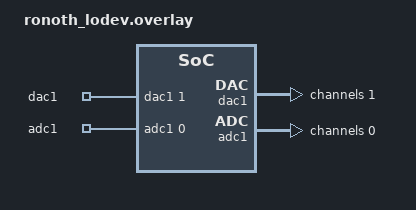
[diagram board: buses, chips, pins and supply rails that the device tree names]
/*
 * Copyright (c) 2021 STMicroelectronics
 *
 * SPDX-License-Identifier: Apache-2.0
 */

/*
 * DAC output on PA4
 * ADC input read from PA0
 * Add a jumper between those two pins to run this test.
 */

/ {
	zephyr,user {
		io-channels = <&dac1 1 &adc1 0>;
		io-channel-names = "dac1", "adc1";
	};
};

&dac1 {
	status = "okay";

	#address-cells = <1>;
	#size-cells = <0>;

	channel@1 {
		reg = <1>;
		zephyr,resolution = <12>;
	};
};

&adc1 {
	status = "okay";

	#address-cells = <1>;
	#size-cells = <0>;

	channel@0 {
		reg = <0>;
		zephyr,gain = "ADC_GAIN_1";
		zephyr,reference = "ADC_REF_INTERNAL";
		zephyr,resolution = <12>;
		zephyr,acquisition-time = <ADC_ACQ_TIME_MAX>;
	};
};
